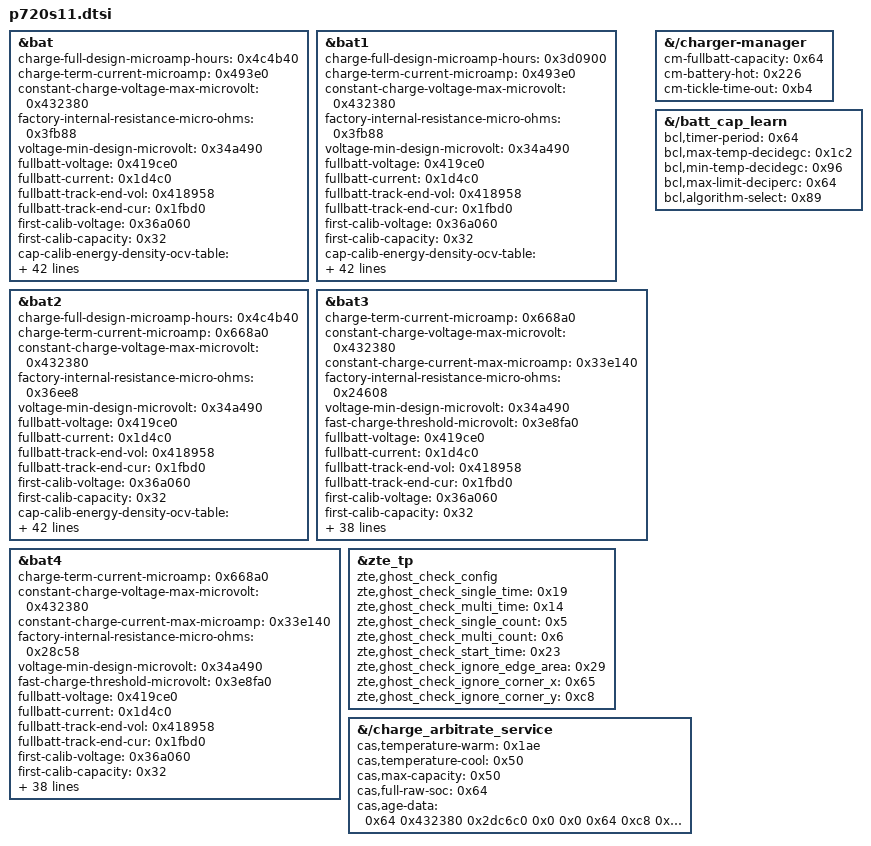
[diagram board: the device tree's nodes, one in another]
/*
 * ZTE P720S11 board-specific overrides recovered from p720s11.dts.
 */

&bat {
	charge-full-design-microamp-hours = <0x4c4b40>;
	charge-term-current-microamp = <0x493e0>;
	constant-charge-voltage-max-microvolt = <0x432380>;
	factory-internal-resistance-micro-ohms = <0x3fb88>;
	voltage-min-design-microvolt = <0x34a490>;
	fullbatt-voltage = <0x419ce0>;
	fullbatt-current = <0x1d4c0>;
	fullbatt-track-end-vol = <0x418958>;
	fullbatt-track-end-cur = <0x1fbd0>;
	first-calib-voltage = <0x36a060>;
	first-calib-capacity = <0x32>;
	cap-calib-energy-density-ocv-table = <0x331df0 0x39fbc0 0x3f52f0 0x426030>;
	cap-track-energy-density-ocv-table = <0x33e140 0x38cb10>;
	ocv-capacity-celsius = <0x19>;
	ocv-capacity-table-0 = <0x422598 0x64 0x414ad8 0x5f 0x407018 0x5a 0x3fa110 0x55 0x3ed5f0 0x50 0x3e1a70 0x4b 0x3d4b68 0x46 0x3ca758 0x41 0x3c0b18 0x3c 0x3b3828 0x37 0x3ac2f8 0x32 0x3a6538 0x2d 0x3a1b00 0x28 0x39dc80 0x23 0x39a1e8 0x1e 0x394fe0 0x19 0x390990 0x14 0x38a7e8 0xf 0x384258 0xa 0x381378 0x5 0x33e140 0x0>;
	voltage-temp-table = <0x17eeb9 0x2ee 0x176a55 0x320 0x171e06 0x352 0x1684eb 0x384 0x1565a2 0x3b6 0x145d16 0x3e8 0x12a633 0x41a 0x11452d 0x44c 0xfcd8e 0x47e 0xe49ea 0x4b0 0xcc5f0 0x4e2 0xb4c59 0x514 0x9e661 0x546 0x89acc 0x578 0x76e19 0x5aa 0x66191 0x5dc 0x575ae 0x60e 0x4a898 0x640 0x3f7e3 0x672 0x360fe 0x6a4 0x2e034 0x6d6>;
	capacity-temp-table = <0x19 0x64 0xa 0x64 0x0 0x62 0xfffffff6 0x5c 0xffffffec 0x3f>;
	resistance-temp-table = <0x19 0x64 0xa 0x83 0x0 0x258 0xfffffff6 0x292 0xffffffec 0x2f8>;
	charge-sdp-current-microamp = <0xaae60 0x7a120>;
	charge-dcp-current-microamp = <0x2ab980 0x1e8480>;
	charge-cdp-current-microamp = <0x2ab980 0x16e360>;
	charge-unknown-current-microamp = <0xf4240 0xf4240>;
	dcp-jeita-temp-table = <0x3e8 0x406 0x0 0x432380 0x41a 0x438 0x124f80 0x432380 0x44c 0x49c 0x124f80 0x432380 0x5aa 0x58c 0x2ab980 0x432380 0x60e 0x5f0 0x1e8480 0x3e8fa0>;
	sdp-jeita-temp-table = <0x3e8 0x406 0x0 0x432380 0x41a 0x438 0x124f80 0x432380 0x44c 0x49c 0x124f80 0x432380 0x5aa 0x58c 0x2ab980 0x432380 0x60e 0x5f0 0x1e8480 0x3e8fa0>;
	cdp-jeita-temp-table = <0x3e8 0x406 0x0 0x432380 0x41a 0x438 0x124f80 0x432380 0x44c 0x49c 0x124f80 0x432380 0x5aa 0x58c 0x2ab980 0x432380 0x60e 0x5f0 0x1e8480 0x3e8fa0>;
	unknown-jeita-temp-table = <0x3e8 0x406 0x0 0x432380 0x41a 0x438 0x124f80 0x432380 0x44c 0x49c 0x124f80 0x432380 0x5aa 0x58c 0x2ab980 0x432380 0x60e 0x5f0 0x1e8480 0x3e8fa0>;
	force-jeita-status = <0x2>;
	constant-charge-current-max-microamp = <0x2ab980>;
	fast-charge-threshold-microvolt = <0x3e8fa0>;
	ir-cv-offset-microvolt = <0x186a0>;
	ir-rc-micro-ohms = <0x4e20>;
	ir-us-upper-limit-microvolt = <0x44aa20>;
	batt-id-list = <0x2 0x2f 0x12c 0x186 0x14>;
	charge-full-microamp-hours = <0x48d0a0>;
	fullbatt-advance-level = <0x3e8>;
	charge-fchg-current-microamp = <0x2ab980 0x1e8480>;
	charge-flash-current-microamp = <0x2ab980 0x1e8480>;
	fchg-jeita-temp-table = <0x3e8 0x406 0x0 0x432380 0x41a 0x438 0x124f80 0x432380 0x44c 0x49c 0x124f80 0x432380 0x5aa 0x58c 0x2ab980 0x432380 0x60e 0x5f0 0x1e8480 0x3e8fa0>;
	flash-jeita-temp-table = <0x3e8 0x406 0x0 0x432380 0x41a 0x438 0x124f80 0x432380 0x44c 0x49c 0x124f80 0x432380 0x5aa 0x58c 0x2ab980 0x432380 0x60e 0x5f0 0x1e8480 0x3e8fa0>;
};

&bat1 {
	charge-full-design-microamp-hours = <0x3d0900>;
	charge-term-current-microamp = <0x493e0>;
	constant-charge-voltage-max-microvolt = <0x432380>;
	factory-internal-resistance-micro-ohms = <0x3fb88>;
	voltage-min-design-microvolt = <0x34a490>;
	fullbatt-voltage = <0x419ce0>;
	fullbatt-current = <0x1d4c0>;
	fullbatt-track-end-vol = <0x418958>;
	fullbatt-track-end-cur = <0x1fbd0>;
	first-calib-voltage = <0x36a060>;
	first-calib-capacity = <0x32>;
	cap-calib-energy-density-ocv-table = <0x331df0 0x39fbc0 0x3f52f0 0x426030>;
	cap-track-energy-density-ocv-table = <0x33e140 0x38cb10>;
	ocv-capacity-celsius = <0x19>;
	ocv-capacity-table-0 = <0x426fd0 0x64 0x416248 0x5f 0x406c30 0x5a 0x3f85b8 0x55 0x3eaee0 0x50 0x3ddbf0 0x4b 0x3d1c88 0x46 0x3c70a8 0x41 0x3bc8b0 0x3c 0x3af5c0 0x37 0x3a6920 0x32 0x3a0b60 0x2d 0x39c128 0x28 0x398e60 0x23 0x397308 0x1e 0x394428 0x19 0x38f9f0 0x14 0x38a018 0xf 0x37f438 0xa 0x36b000 0x5 0x33e140 0x0>;
	voltage-temp-table = <0x17eeb9 0x2ee 0x176a55 0x320 0x171e06 0x352 0x1684eb 0x384 0x1565a2 0x3b6 0x145d16 0x3e8 0x12a633 0x41a 0x11452d 0x44c 0xfcd8e 0x47e 0xe49ea 0x4b0 0xcc5f0 0x4e2 0xb4c59 0x514 0x9e661 0x546 0x89acc 0x578 0x76e19 0x5aa 0x66191 0x5dc 0x575ae 0x60e 0x4a898 0x640 0x3f7e3 0x672 0x360fe 0x6a4 0x2e034 0x6d6>;
	capacity-temp-table = <0x19 0x64 0xa 0x64 0x0 0x5b 0xfffffff6 0x48 0xffffffec 0x27>;
	resistance-temp-table = <0x19 0x64 0xa 0xf2 0x0 0x175 0xfffffff6 0x1bf 0xffffffec 0x23b>;
	charge-sdp-current-microamp = <0xaae60 0x7a120>;
	charge-dcp-current-microamp = <0x2ab980 0x1e8480>;
	charge-cdp-current-microamp = <0x2ab980 0x16e360>;
	charge-unknown-current-microamp = <0xf4240 0xf4240>;
	dcp-jeita-temp-table = <0x3e8 0x406 0x0 0x432380 0x41a 0x438 0x124f80 0x432380 0x44c 0x49c 0x124f80 0x432380 0x5aa 0x58c 0x2ab980 0x432380 0x60e 0x5f0 0x1e8480 0x3e8fa0>;
	sdp-jeita-temp-table = <0x3e8 0x406 0x0 0x432380 0x41a 0x438 0x124f80 0x432380 0x44c 0x49c 0x124f80 0x432380 0x5aa 0x58c 0x2ab980 0x432380 0x60e 0x5f0 0x1e8480 0x3e8fa0>;
	cdp-jeita-temp-table = <0x3e8 0x406 0x0 0x432380 0x41a 0x438 0x124f80 0x432380 0x44c 0x49c 0x124f80 0x432380 0x5aa 0x58c 0x2ab980 0x432380 0x60e 0x5f0 0x1e8480 0x3e8fa0>;
	unknown-jeita-temp-table = <0x3e8 0x406 0x0 0x432380 0x41a 0x438 0x124f80 0x432380 0x44c 0x49c 0x124f80 0x432380 0x5aa 0x58c 0x2ab980 0x432380 0x60e 0x5f0 0x1e8480 0x3e8fa0>;
	force-jeita-status = <0x2>;
	constant-charge-current-max-microamp = <0x2ab980>;
	fast-charge-threshold-microvolt = <0x3e8fa0>;
	ir-cv-offset-microvolt = <0x186a0>;
	ir-rc-micro-ohms = <0x4e20>;
	ir-us-upper-limit-microvolt = <0x44aa20>;
	batt-id-list = <0x2 0x2f 0x12c 0x186 0x14>;
	charge-full-microamp-hours = <0x392100>;
	fullbatt-advance-level = <0x3e8>;
	charge-fchg-current-microamp = <0x2ab980 0x1e8480>;
	charge-flash-current-microamp = <0x2ab980 0x1e8480>;
	fchg-jeita-temp-table = <0x3e8 0x406 0x0 0x432380 0x41a 0x438 0x124f80 0x432380 0x44c 0x49c 0x124f80 0x432380 0x5aa 0x58c 0x2ab980 0x432380 0x60e 0x5f0 0x1e8480 0x3e8fa0>;
	flash-jeita-temp-table = <0x3e8 0x406 0x0 0x432380 0x41a 0x438 0x124f80 0x432380 0x44c 0x49c 0x124f80 0x432380 0x5aa 0x58c 0x2ab980 0x432380 0x60e 0x5f0 0x1e8480 0x3e8fa0>;
};

&bat2 {
	charge-full-design-microamp-hours = <0x4c4b40>;
	charge-term-current-microamp = <0x668a0>;
	constant-charge-voltage-max-microvolt = <0x432380>;
	factory-internal-resistance-micro-ohms = <0x36ee8>;
	voltage-min-design-microvolt = <0x34a490>;
	fullbatt-voltage = <0x419ce0>;
	fullbatt-current = <0x1d4c0>;
	fullbatt-track-end-vol = <0x418958>;
	fullbatt-track-end-cur = <0x1fbd0>;
	first-calib-voltage = <0x36a060>;
	first-calib-capacity = <0x32>;
	cap-calib-energy-density-ocv-table = <0x331df0 0x39fbc0 0x3f52f0 0x426030>;
	cap-track-energy-density-ocv-table = <0x33e140 0x38cb10>;
	ocv-capacity-celsius = <0x19>;
	ocv-capacity-table-0 = <0x42bdf0 0x64 0x41bc20 0x5f 0x40d990 0x5a 0x3ffae8 0x55 0x3f27f8 0x50 0x3e58f0 0x4b 0x3d9988 0x46 0x3ce9c0 0x41 0x3c4998 0x3c 0x3b72c0 0x37 0x3ae620 0x32 0x3a8860 0x2d 0x3a3270 0x28 0x39f008 0x23 0x39bd40 0x1e 0x397ad8 0x19 0x393488 0x14 0x38dab0 0xf 0x386968 0xa 0x3832b8 0x5 0x33e140 0x0>;
	voltage-temp-table = <0x17eeb9 0x2ee 0x176a55 0x320 0x171e06 0x352 0x1684eb 0x384 0x1565a2 0x3b6 0x145d16 0x3e8 0x12a633 0x41a 0x11452d 0x44c 0xfcd8e 0x47e 0xe49ea 0x4b0 0xcc5f0 0x4e2 0xb4c59 0x514 0x9e661 0x546 0x89acc 0x578 0x76e19 0x5aa 0x66191 0x5dc 0x575ae 0x60e 0x4a898 0x640 0x3f7e3 0x672 0x360fe 0x6a4 0x2e034 0x6d6>;
	capacity-temp-table = <0x19 0x64 0xa 0x64 0x0 0x61 0xfffffff6 0x59 0xffffffec 0x39>;
	resistance-temp-table = <0x19 0x64 0xa 0x14c 0x0 0x1fb 0xfffffff6 0x239 0xffffffec 0x2a3>;
	charge-sdp-current-microamp = <0xaae60 0x7a120>;
	charge-dcp-current-microamp = <0x33e140 0x1e8480>;
	charge-cdp-current-microamp = <0x33e140 0x16e360>;
	charge-unknown-current-microamp = <0xf4240 0xf4240>;
	dcp-jeita-temp-table = <0x3e8 0x406 0x0 0x432380 0x41a 0x438 0x155cc0 0x432380 0x44c 0x49c 0x155cc0 0x432380 0x5aa 0x58c 0x33e140 0x432380 0x60e 0x5f0 0x249f00 0x3e8fa0>;
	sdp-jeita-temp-table = <0x3e8 0x406 0x0 0x432380 0x41a 0x438 0x155cc0 0x432380 0x44c 0x49c 0x155cc0 0x432380 0x5aa 0x58c 0x33e140 0x432380 0x60e 0x5f0 0x249f00 0x3e8fa0>;
	cdp-jeita-temp-table = <0x3e8 0x406 0x0 0x432380 0x41a 0x438 0x155cc0 0x432380 0x44c 0x49c 0x155cc0 0x432380 0x5aa 0x58c 0x33e140 0x432380 0x60e 0x5f0 0x249f00 0x3e8fa0>;
	unknown-jeita-temp-table = <0x3e8 0x406 0x0 0x432380 0x41a 0x438 0x155cc0 0x432380 0x44c 0x49c 0x155cc0 0x432380 0x5aa 0x58c 0x33e140 0x432380 0x60e 0x5f0 0x249f00 0x3e8fa0>;
	force-jeita-status = <0x2>;
	constant-charge-current-max-microamp = <0x33e140>;
	fast-charge-threshold-microvolt = <0x3e8fa0>;
	ir-cv-offset-microvolt = <0x186a0>;
	ir-rc-micro-ohms = <0x4e20>;
	ir-us-upper-limit-microvolt = <0x44aa20>;
	batt-id-list = <0x2 0x2f 0x12c 0x186 0x14>;
	charge-full-microamp-hours = <0x48d0a0>;
	fullbatt-advance-level = <0x3e8>;
	charge-fchg-current-microamp = <0x33e140 0x1e8480>;
	charge-flash-current-microamp = <0x33e140 0x1e8480>;
	fchg-jeita-temp-table = <0x3e8 0x406 0x0 0x432380 0x41a 0x438 0x155cc0 0x432380 0x44c 0x49c 0x155cc0 0x432380 0x5aa 0x58c 0x33e140 0x432380 0x60e 0x5f0 0x249f00 0x3e8fa0>;
	flash-jeita-temp-table = <0x3e8 0x406 0x0 0x432380 0x41a 0x438 0x155cc0 0x432380 0x44c 0x49c 0x155cc0 0x432380 0x5aa 0x58c 0x33e140 0x432380 0x60e 0x5f0 0x249f00 0x3e8fa0>;
};

&bat3 {
	charge-term-current-microamp = <0x668a0>;
	constant-charge-voltage-max-microvolt = <0x432380>;
	constant-charge-current-max-microamp = <0x33e140>;
	factory-internal-resistance-micro-ohms = <0x24608>;
	voltage-min-design-microvolt = <0x34a490>;
	fast-charge-threshold-microvolt = <0x3e8fa0>;
	fullbatt-voltage = <0x419ce0>;
	fullbatt-current = <0x1d4c0>;
	fullbatt-track-end-vol = <0x418958>;
	fullbatt-track-end-cur = <0x1fbd0>;
	first-calib-voltage = <0x36a060>;
	first-calib-capacity = <0x32>;
	ir-cv-offset-microvolt = <0x186a0>;
	ir-rc-micro-ohms = <0x4e20>;
	ir-us-upper-limit-microvolt = <0x44aa20>;
	ocv-capacity-celsius = <0x19>;
	charge-full-design-microamp-hours = <0x4c4b40>;
	charge-full-microamp-hours = <0x48d0a0>;
	fullbatt-advance-level = <0x3e8>;
	batt-id-list = <0x2 0x2f 0x12c 0x186 0x14>;
	ocv-capacity-table-0 = <0x420a40 0x64 0x411040 0x5f 0x403198 0x5a 0x3f5ac0 0x55 0x3e8bb8 0x50 0x3de7a8 0x4b 0x3ce5d8 0x46 0x3c68d8 0x41 0x3bc8b0 0x3c 0x3afd90 0x37 0x3a8478 0x32 0x3a2aa0 0x2d 0x39e450 0x28 0x39ada0 0x23 0x397ad8 0x1e 0x393870 0x19 0x38f608 0x14 0x389848 0xf 0x382ae8 0xa 0x3803d8 0x5 0x33e140 0x0>;
	voltage-temp-table = <0x17eeb9 0x2ee 0x176a55 0x320 0x171e06 0x352 0x1684eb 0x384 0x1565a2 0x3b6 0x145d16 0x3e8 0x12a633 0x41a 0x11452d 0x44c 0xfcd8e 0x47e 0xe49ea 0x4b0 0xcc5f0 0x4e2 0xb4c59 0x514 0x9e661 0x546 0x89acc 0x578 0x76e19 0x5aa 0x66191 0x5dc 0x575ae 0x60e 0x4a898 0x640 0x3f7e3 0x672 0x360fe 0x6a4 0x2e034 0x6d6>;
	capacity-temp-table = <0x19 0x64 0xa 0x64 0x0 0x61 0xfffffff6 0x5f 0xffffffec 0x53>;
	resistance-temp-table = <0x19 0x64 0xa 0xb2 0x0 0x2d5 0xfffffff6 0x32c 0xffffffec 0x37e>;
	charge-sdp-current-microamp = <0xaae60 0x7a120>;
	charge-dcp-current-microamp = <0x33e140 0x1e8480>;
	charge-cdp-current-microamp = <0x33e140 0x16e360>;
	charge-unknown-current-microamp = <0xf4240 0xf4240>;
	dcp-jeita-temp-table = <0x3e8 0x406 0x0 0x432380 0x41a 0x438 0x155cc0 0x432380 0x44c 0x49c 0x155cc0 0x432380 0x5aa 0x58c 0x33e140 0x432380 0x60e 0x5f0 0x249f00 0x3e8fa0>;
	sdp-jeita-temp-table = <0x3e8 0x406 0x0 0x432380 0x41a 0x438 0x155cc0 0x432380 0x44c 0x49c 0x155cc0 0x432380 0x5aa 0x58c 0x33e140 0x432380 0x60e 0x5f0 0x249f00 0x3e8fa0>;
	cdp-jeita-temp-table = <0x3e8 0x406 0x0 0x432380 0x41a 0x438 0x155cc0 0x432380 0x44c 0x49c 0x155cc0 0x432380 0x5aa 0x58c 0x33e140 0x432380 0x60e 0x5f0 0x249f00 0x3e8fa0>;
	unknown-jeita-temp-table = <0x3e8 0x406 0x0 0x432380 0x41a 0x438 0x155cc0 0x432380 0x44c 0x49c 0x155cc0 0x432380 0x5aa 0x58c 0x33e140 0x432380 0x60e 0x5f0 0x249f00 0x3e8fa0>;
	force-jeita-status = <0x2>;
	charge-fchg-current-microamp = <0x33e140 0x1e8480>;
	charge-flash-current-microamp = <0x33e140 0x1e8480>;
	fchg-jeita-temp-table = <0x3e8 0x406 0x0 0x432380 0x41a 0x438 0x155cc0 0x432380 0x44c 0x49c 0x155cc0 0x432380 0x5aa 0x58c 0x33e140 0x432380 0x60e 0x5f0 0x249f00 0x3e8fa0>;
	flash-jeita-temp-table = <0x3e8 0x406 0x0 0x432380 0x41a 0x438 0x155cc0 0x432380 0x44c 0x49c 0x155cc0 0x432380 0x5aa 0x58c 0x33e140 0x432380 0x60e 0x5f0 0x249f00 0x3e8fa0>;
};

&bat4 {
	charge-term-current-microamp = <0x668a0>;
	constant-charge-voltage-max-microvolt = <0x432380>;
	constant-charge-current-max-microamp = <0x33e140>;
	factory-internal-resistance-micro-ohms = <0x28c58>;
	voltage-min-design-microvolt = <0x34a490>;
	fast-charge-threshold-microvolt = <0x3e8fa0>;
	fullbatt-voltage = <0x419ce0>;
	fullbatt-current = <0x1d4c0>;
	fullbatt-track-end-vol = <0x418958>;
	fullbatt-track-end-cur = <0x1fbd0>;
	first-calib-voltage = <0x36a060>;
	first-calib-capacity = <0x32>;
	ir-cv-offset-microvolt = <0x186a0>;
	ir-rc-micro-ohms = <0x4e20>;
	ir-us-upper-limit-microvolt = <0x44aa20>;
	ocv-capacity-celsius = <0x19>;
	charge-full-design-microamp-hours = <0x4c4b40>;
	charge-full-microamp-hours = <0x48d0a0>;
	fullbatt-advance-level = <0x3e8>;
	batt-id-list = <0x2 0x2f 0x12c 0x186 0x14>;
	ocv-capacity-table-0 = <0x420e28 0x64 0x411428 0x5f 0x403198 0x5a 0x3f5ac0 0x55 0x3e8bb8 0x50 0x3dc868 0x4b 0x3d0ce8 0x46 0x3c70a8 0x41 0x3bd468 0x3c 0x3afd90 0x37 0x3a78c0 0x32 0x3a22d0 0x2d 0x39e068 0x28 0x39a9b8 0x23 0x397ec0 0x1e 0x394bf8 0x19 0x390990 0x14 0x38b3a0 0xf 0x382ae8 0xa 0x37c170 0x5 0x33e140 0x0>;
	voltage-temp-table = <0x17eeb9 0x2ee 0x176a55 0x320 0x171e06 0x352 0x1684eb 0x384 0x1565a2 0x3b6 0x145d16 0x3e8 0x12a633 0x41a 0x11452d 0x44c 0xfcd8e 0x47e 0xe49ea 0x4b0 0xcc5f0 0x4e2 0xb4c59 0x514 0x9e661 0x546 0x89acc 0x578 0x76e19 0x5aa 0x66191 0x5dc 0x575ae 0x60e 0x4a898 0x640 0x3f7e3 0x672 0x360fe 0x6a4 0x2e034 0x6d6>;
	capacity-temp-table = <0x19 0x64 0xa 0x64 0x0 0x62 0xfffffff6 0x5a 0xffffffec 0x44>;
	resistance-temp-table = <0x19 0x64 0xa 0x96 0x0 0x1ad 0xfffffff6 0x219 0xffffffec 0x2b2>;
	charge-sdp-current-microamp = <0xaae60 0x7a120>;
	charge-dcp-current-microamp = <0x33e140 0x1e8480>;
	charge-cdp-current-microamp = <0x33e140 0x16e360>;
	charge-unknown-current-microamp = <0xf4240 0xf4240>;
	dcp-jeita-temp-table = <0x3e8 0x406 0x0 0x432380 0x41a 0x438 0x155cc0 0x432380 0x44c 0x49c 0x155cc0 0x432380 0x5aa 0x58c 0x33e140 0x432380 0x60e 0x5f0 0x249f00 0x3e8fa0>;
	sdp-jeita-temp-table = <0x3e8 0x406 0x0 0x432380 0x41a 0x438 0x155cc0 0x432380 0x44c 0x49c 0x155cc0 0x432380 0x5aa 0x58c 0x33e140 0x432380 0x60e 0x5f0 0x249f00 0x3e8fa0>;
	cdp-jeita-temp-table = <0x3e8 0x406 0x0 0x432380 0x41a 0x438 0x155cc0 0x432380 0x44c 0x49c 0x155cc0 0x432380 0x5aa 0x58c 0x33e140 0x432380 0x60e 0x5f0 0x249f00 0x3e8fa0>;
	unknown-jeita-temp-table = <0x3e8 0x406 0x0 0x432380 0x41a 0x438 0x155cc0 0x432380 0x44c 0x49c 0x155cc0 0x432380 0x5aa 0x58c 0x33e140 0x432380 0x60e 0x5f0 0x249f00 0x3e8fa0>;
	force-jeita-status = <0x2>;
	charge-fchg-current-microamp = <0x33e140 0x1e8480>;
	charge-flash-current-microamp = <0x33e140 0x1e8480>;
	fchg-jeita-temp-table = <0x3e8 0x406 0x0 0x432380 0x41a 0x438 0x155cc0 0x432380 0x44c 0x49c 0x155cc0 0x432380 0x5aa 0x58c 0x33e140 0x432380 0x60e 0x5f0 0x249f00 0x3e8fa0>;
	flash-jeita-temp-table = <0x3e8 0x406 0x0 0x432380 0x41a 0x438 0x155cc0 0x432380 0x44c 0x49c 0x155cc0 0x432380 0x5aa 0x58c 0x33e140 0x432380 0x60e 0x5f0 0x249f00 0x3e8fa0>;
};

&zte_tp {
	zte,ghost_check_config;
	zte,ghost_check_single_time = <0x19>;
	zte,ghost_check_multi_time = <0x14>;
	zte,ghost_check_single_count = <0x5>;
	zte,ghost_check_multi_count = <0x6>;
	zte,ghost_check_start_time = <0x23>;
	zte,ghost_check_ignore_edge_area = <0x29>;
	zte,ghost_check_ignore_corner_x = <0x65>;
	zte,ghost_check_ignore_corner_y = <0xc8>;
};

&{/charger-manager} {
	cm-fullbatt-capacity = <0x64>;
	cm-battery-hot = <0x226>;
	cm-tickle-time-out = <0xb4>;
};

&{/batt_cap_learn} {
	bcl,timer-period = <0x64>;
	bcl,max-temp-decidegc = <0x1c2>;
	bcl,min-temp-decidegc = <0x96>;
	bcl,max-limit-deciperc = <0x64>;
	bcl,algorithm-select = <0x89>;
};

&{/charge_arbitrate_service} {
	cas,temperature-warm = <0x1ae>;
	cas,temperature-cool = <0x50>;
	cas,max-capacity = <0x50>;
	cas,full-raw-soc = <0x64>;
	cas,age-data = <0x64 0x432380 0x2dc6c0 0x0 0x0 0x64 0xc8 0x5f 0x42d560 0x2b7cd0 0x0 0x0 0x64 0xc8 0x5a 0x428740 0x2932e0 0x0 0x0 0x64 0xc8 0x55 0x423920 0x26e8f0 0x0 0x0 0xc8 0xc8 0x50 0x41eb00 0x249f00 0x0 0x0 0xc8 0xc8 0x4b 0x419ce0 0x225510 0x0 0x0 0xc8 0xc8>;
};
